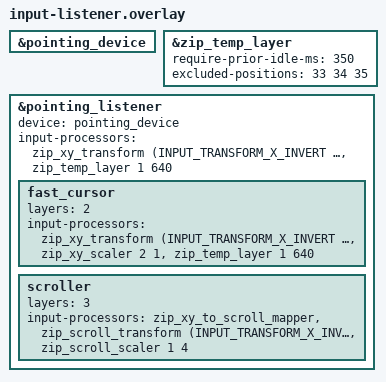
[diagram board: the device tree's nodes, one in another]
&pointing_device {
    status = "okay";
};

/* AML (Auto Mouse Layer) の挙動調整（KobitoKey と同じ設定）
 * - require-prior-idle-ms: 最後のキー入力から 350ms 以内はボールが動いても layer_1 に入らない
 *   （タイピング中にボールに触れて J/K/L がクリックに化けるのを防ぐ）
 * - excluded-positions: layer_1 のクリックキー（J=33, K=34, L=35）を押しても layer_1 を抜けない
 *   （ダブルクリックやドラッグ中にレイヤーが外れて文字が入力されるのを防ぐ）
 *   ※ 位置番号は config/keymap.keymap の L Layout 基準。クリックキーを動かしたらここも直すこと
 */
&zip_temp_layer {
    require-prior-idle-ms = <350>;
    excluded-positions = <33 34 35>;
};
&pointing_listener {
    status = "okay";
    device = <&pointing_device>;

    input-processors = 
        <&zip_xy_transform (INPUT_TRANSFORM_X_INVERT | INPUT_TRANSFORM_Y_INVERT)>, 
        <&zip_temp_layer 1 640>;

    fast_cursor {
        layers = <2>;
        input-processors = 
            <&zip_xy_transform (INPUT_TRANSFORM_X_INVERT | INPUT_TRANSFORM_Y_INVERT)>, 
            <&zip_xy_scaler 2 1>,
            <&zip_temp_layer 1 640>;
    };
    
    scroller {
        layers = <3>;
        input-processors = 
            <&zip_xy_to_scroll_mapper>, 
            <&zip_scroll_transform (INPUT_TRANSFORM_X_INVERT)>, 
            <&zip_scroll_scaler 1 4>;
    };
};
